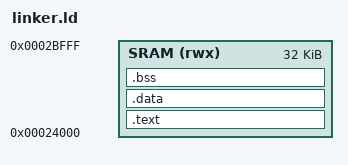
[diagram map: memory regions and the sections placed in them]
ENTRY(_start)

MEMORY
{
    SRAM (rwx) : ORIGIN = 0x00024000, LENGTH = 32K
}

SECTIONS
{
    .text : {
        *(.text.start)
        *(.text*)
        *(.rodata*)
    } > SRAM

    .data : {
        *(.data*)
    } > SRAM

    .bss : {
        __bss_start = .;
        *(.bss*)
        *(COMMON)
        __bss_end = .;
    } > SRAM

    _stack_top = ORIGIN(SRAM) + LENGTH(SRAM);
}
